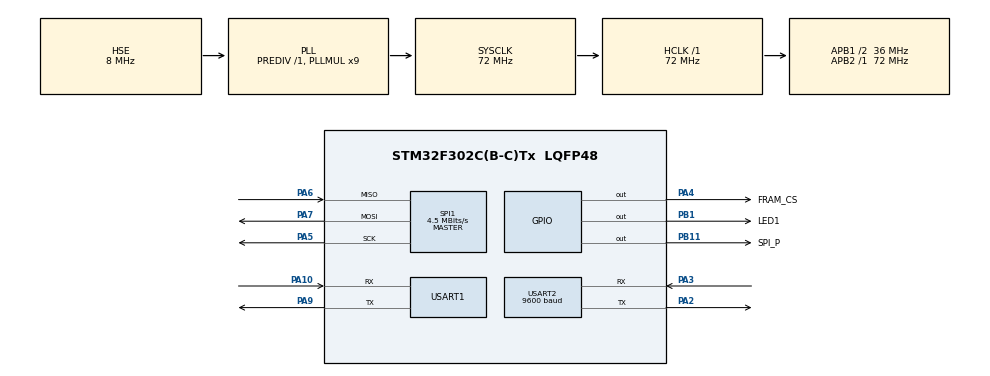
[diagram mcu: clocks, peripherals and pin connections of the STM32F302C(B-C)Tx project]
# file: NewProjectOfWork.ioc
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Dma.Request0=USART1_TX
Dma.Request1=USART1_RX
Dma.Request2=SPI1_TX
Dma.Request3=SPI1_RX
Dma.Request4=USART2_RX
Dma.Request5=USART2_TX
Dma.SPI1_RX.3.Direction=DMA_PERIPH_TO_MEMORY
Dma.SPI1_RX.3.Instance=DMA1_Channel2
Dma.SPI1_RX.3.MemDataAlignment=DMA_MDATAALIGN_BYTE
Dma.SPI1_RX.3.MemInc=DMA_MINC_ENABLE
Dma.SPI1_RX.3.Mode=DMA_NORMAL
Dma.SPI1_RX.3.PeriphDataAlignment=DMA_PDATAALIGN_BYTE
Dma.SPI1_RX.3.PeriphInc=DMA_PINC_DISABLE
Dma.SPI1_RX.3.Priority=DMA_PRIORITY_LOW
Dma.SPI1_TX.2.Direction=DMA_MEMORY_TO_PERIPH
Dma.SPI1_TX.2.Instance=DMA1_Channel3
Dma.SPI1_TX.2.MemDataAlignment=DMA_MDATAALIGN_BYTE
Dma.SPI1_TX.2.MemInc=DMA_MINC_ENABLE
Dma.SPI1_TX.2.Mode=DMA_NORMAL
Dma.SPI1_TX.2.PeriphDataAlignment=DMA_PDATAALIGN_BYTE
Dma.SPI1_TX.2.PeriphInc=DMA_PINC_DISABLE
Dma.SPI1_TX.2.Priority=DMA_PRIORITY_LOW
Dma.USART1_RX.1.Direction=DMA_PERIPH_TO_MEMORY
Dma.USART1_RX.1.Instance=DMA1_Channel5
Dma.USART1_RX.1.MemDataAlignment=DMA_MDATAALIGN_BYTE
Dma.USART1_RX.1.MemInc=DMA_MINC_ENABLE
Dma.USART1_RX.1.Mode=DMA_NORMAL
Dma.USART1_RX.1.PeriphDataAlignment=DMA_PDATAALIGN_BYTE
Dma.USART1_RX.1.PeriphInc=DMA_PINC_DISABLE
Dma.USART1_RX.1.Priority=DMA_PRIORITY_LOW
Dma.USART1_TX.0.Direction=DMA_MEMORY_TO_PERIPH
Dma.USART1_TX.0.Instance=DMA1_Channel4
Dma.USART1_TX.0.MemDataAlignment=DMA_MDATAALIGN_BYTE
Dma.USART1_TX.0.MemInc=DMA_MINC_ENABLE
Dma.USART1_TX.0.Mode=DMA_NORMAL
Dma.USART1_TX.0.PeriphDataAlignment=DMA_PDATAALIGN_BYTE
Dma.USART1_TX.0.PeriphInc=DMA_PINC_DISABLE
Dma.USART1_TX.0.Priority=DMA_PRIORITY_LOW
Dma.USART2_RX.4.Direction=DMA_PERIPH_TO_MEMORY
Dma.USART2_RX.4.Instance=DMA1_Channel6
Dma.USART2_RX.4.MemDataAlignment=DMA_MDATAALIGN_BYTE
Dma.USART2_RX.4.MemInc=DMA_MINC_ENABLE
Dma.USART2_RX.4.Mode=DMA_NORMAL
Dma.USART2_RX.4.PeriphDataAlignment=DMA_PDATAALIGN_BYTE
Dma.USART2_RX.4.PeriphInc=DMA_PINC_DISABLE
Dma.USART2_RX.4.Priority=DMA_PRIORITY_LOW
Dma.USART2_TX.5.Direction=DMA_MEMORY_TO_PERIPH
Dma.USART2_TX.5.Instance=DMA1_Channel7
Dma.USART2_TX.5.MemDataAlignment=DMA_MDATAALIGN_BYTE
Dma.USART2_TX.5.MemInc=DMA_MINC_ENABLE
Dma.USART2_TX.5.Mode=DMA_NORMAL
Dma.USART2_TX.5.PeriphDataAlignment=DMA_PDATAALIGN_BYTE
Dma.USART2_TX.5.PeriphInc=DMA_PINC_DISABLE
Dma.USART2_TX.5.Priority=DMA_PRIORITY_LOW
Mcu.Family=STM32F3
Mcu.Name=STM32F302C(B-C)Tx
Mcu.Package=LQFP48
NVIC.DMA1_Channel2_IRQn=true\:0\:0\:false\:false\:true\:false\:true\:true
NVIC.DMA1_Channel3_IRQn=true\:0\:0\:false\:false\:true\:false\:true\:true
NVIC.DMA1_Channel4_IRQn=true\:0\:0\:false\:false\:true\:false\:true\:true
NVIC.DMA1_Channel5_IRQn=true\:0\:0\:false\:false\:true\:false\:true\:true
NVIC.DMA1_Channel6_IRQn=true\:0\:0\:false\:false\:true\:false\:true\:true
NVIC.DMA1_Channel7_IRQn=true\:0\:0\:false\:false\:true\:false\:true\:true
NVIC.PriorityGroup=NVIC_PRIORITYGROUP_4
NVIC.RCC_IRQn=true\:0\:0\:false\:false\:true\:true\:false\:true
NVIC.SPI1_IRQn=true\:0\:0\:false\:false\:true\:true\:true\:true
NVIC.USART1_IRQn=true\:0\:0\:false\:false\:true\:true\:true\:true
NVIC.USART2_IRQn=true\:0\:0\:false\:false\:true\:true\:true\:true
PA10.Mode=Asynchronous
PA10.Signal=USART1_RX
PA13.Mode=Serial_Wire
PA13.Signal=SYS_JTMS-SWDIO
PA14.Mode=Serial_Wire
PA14.Signal=SYS_JTCK-SWCLK
PA2.Mode=Asynchronous
PA2.Signal=USART2_TX
PA3.Mode=Asynchronous
PA3.Signal=USART2_RX
PA4.GPIO_Label=FRAM_CS
PA4.GPIO_ModeDefaultOutputPP=GPIO_MODE_OUTPUT_PP
PA4.GPIO_Speed=GPIO_SPEED_FREQ_HIGH
PA4.PinState=GPIO_PIN_SET
PA4.Signal=GPIO_Output
PA5.Mode=Full_Duplex_Master
PA5.Signal=SPI1_SCK
PA6.Mode=Full_Duplex_Master
PA6.Signal=SPI1_MISO
PA7.Mode=Full_Duplex_Master
PA7.Signal=SPI1_MOSI
PA9.Mode=Asynchronous
PA9.Signal=USART1_TX
PB1.GPIO_Label=LED1
PB1.Signal=GPIO_Output
PB11.GPIO_Label=SPI_P
PB11.Signal=GPIO_Output
PF0-OSC_IN.Mode=HSE-External-Oscillator
PF0-OSC_IN.Signal=RCC_OSC_IN
PF1-OSC_OUT.Mode=HSE-External-Oscillator
PF1-OSC_OUT.Signal=RCC_OSC_OUT
ProjectManager.HeapSize=0x200
ProjectManager.StackSize=0x400
ProjectManager.TargetToolchain=MDK-ARM V5.32
RCC.AHBFreq_Value=72000000
RCC.APB1CLKDivider=RCC_HCLK_DIV2
RCC.APB1Freq_Value=36000000
RCC.APB1TimFreq_Value=72000000
RCC.APB2Freq_Value=72000000
RCC.APB2TimFreq_Value=72000000
RCC.CortexFreq_Value=72000000
RCC.HCLKFreq_Value=72000000
RCC.HSE_VALUE=8000000
RCC.HSI_VALUE=8000000
RCC.LSE_VALUE=32768
RCC.PLLMUL=RCC_PLL_MUL9
RCC.PLLSourceVirtual=RCC_PLLSOURCE_HSE
RCC.SYSCLKFreq_VALUE=72000000
RCC.SYSCLKSourceVirtual=RCC_SYSCLKSOURCE_PLLCLK
RCC.USBFreq_Value=72000000
SPI1.BaudRatePrescaler=SPI_BAUDRATEPRESCALER_16
SPI1.CalculateBaudRate=4.5 MBits/s
SPI1.DataSize=SPI_DATASIZE_8BIT
SPI1.Direction=SPI_DIRECTION_2LINES
SPI1.Mode=SPI_MODE_MASTER
SPI1.VirtualType=VM_MASTER
USART1.VirtualMode-Asynchronous=VM_ASYNC
USART1.WordLength=WORDLENGTH_8B
USART2.BaudRate=9600
USART2.VirtualMode-Asynchronous=VM_ASYNC
board=custom

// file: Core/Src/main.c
/* USER CODE BEGIN Header */
/**
  ******************************************************************************
  * @file           : main.c
  * @brief          : Main program body
  ******************************************************************************
  * @attention
  *
  * Copyright (c) 2024 STMicroelectronics.
  * All rights reserved.
  *
  * This software is licensed under terms that can be found in the LICENSE file
  * in the root directory of this software component.
  * If no LICENSE file comes with this software, it is provided AS-IS.
  *
  ******************************************************************************
  */
/* USER CODE END Header */
#include "main.h"
#include "dma.h"
#include "spi.h"
#include "usart.h"
#include "gpio.h"

/* USER CODE BEGIN Includes */

#include "board.h"
#include "usartuser.h"
#include "spiuser.h"

/* USER CODE END Includes */

void SystemClock_Config(void);

int main(void)
{

  /* MCU Configuration--------------------------------------------------------*/

  /* Reset of all peripherals, Initializes the Flash interface and the Systick. */
  HAL_Init();

  /* Configure the system clock */
  SystemClock_Config();

  /* Initialize all configured peripherals */
  MX_GPIO_Init();
  MX_DMA_Init();
  MX_USART1_UART_Init();
  MX_SPI1_Init();
  MX_USART2_UART_Init();
  /* USER CODE BEGIN 2 */

  board_Init(); // 结构初始化
  usartuser_Init(); // 自定义串口通信初始化
  spiuser_Init();

  /* USER CODE END 2 */

  /* Infinite loop */
  /* USER CODE BEGIN WHILE */
  while (1)
  {
      //准备推图，2024.12.16
      board_quick();
      board_slow();
      board_ticks_handle();

    /* USER CODE END WHILE */

  }
}

void SystemClock_Config(void)
{
  RCC_OscInitTypeDef RCC_OscInitStruct = {0};
  RCC_ClkInitTypeDef RCC_ClkInitStruct = {0};
  RCC_PeriphCLKInitTypeDef PeriphClkInit = {0};

  /** Initializes the RCC Oscillators according to the specified parameters
  * in the RCC_OscInitTypeDef structure.
  */
  RCC_OscInitStruct.OscillatorType = RCC_OSCILLATORTYPE_HSE;
  RCC_OscInitStruct.HSEState = RCC_HSE_ON;
  RCC_OscInitStruct.HSEPredivValue = RCC_HSE_PREDIV_DIV1;
  RCC_OscInitStruct.HSIState = RCC_HSI_ON;
  RCC_OscInitStruct.PLL.PLLState = RCC_PLL_ON;
  RCC_OscInitStruct.PLL.PLLSource = RCC_PLLSOURCE_HSE;
  RCC_OscInitStruct.PLL.PLLMUL = RCC_PLL_MUL9;
  if (HAL_RCC_OscConfig(&RCC_OscInitStruct) != HAL_OK)
  {
    Error_Handler();
  }

  /** Initializes the CPU, AHB and APB buses clocks
  */
  RCC_ClkInitStruct.ClockType = RCC_CLOCKTYPE_HCLK|RCC_CLOCKTYPE_SYSCLK
                              |RCC_CLOCKTYPE_PCLK1|RCC_CLOCKTYPE_PCLK2;
  RCC_ClkInitStruct.SYSCLKSource = RCC_SYSCLKSOURCE_PLLCLK;
  RCC_ClkInitStruct.AHBCLKDivider = RCC_SYSCLK_DIV1;
  RCC_ClkInitStruct.APB1CLKDivider = RCC_HCLK_DIV2;
  RCC_ClkInitStruct.APB2CLKDivider = RCC_HCLK_DIV1;

  if (HAL_RCC_ClockConfig(&RCC_ClkInitStruct, FLASH_LATENCY_2) != HAL_OK)
  {
    Error_Handler();
  }
  PeriphClkInit.PeriphClockSelection = RCC_PERIPHCLK_USART1|RCC_PERIPHCLK_USART2;
  PeriphClkInit.Usart1ClockSelection = RCC_USART1CLKSOURCE_PCLK2;
  PeriphClkInit.Usart2ClockSelection = RCC_USART2CLKSOURCE_PCLK1;
  if (HAL_RCCEx_PeriphCLKConfig(&PeriphClkInit) != HAL_OK)
  {
    Error_Handler();
  }
}

void Error_Handler(void)
{
  __disable_irq();
  while (1)
  {
  }
}
